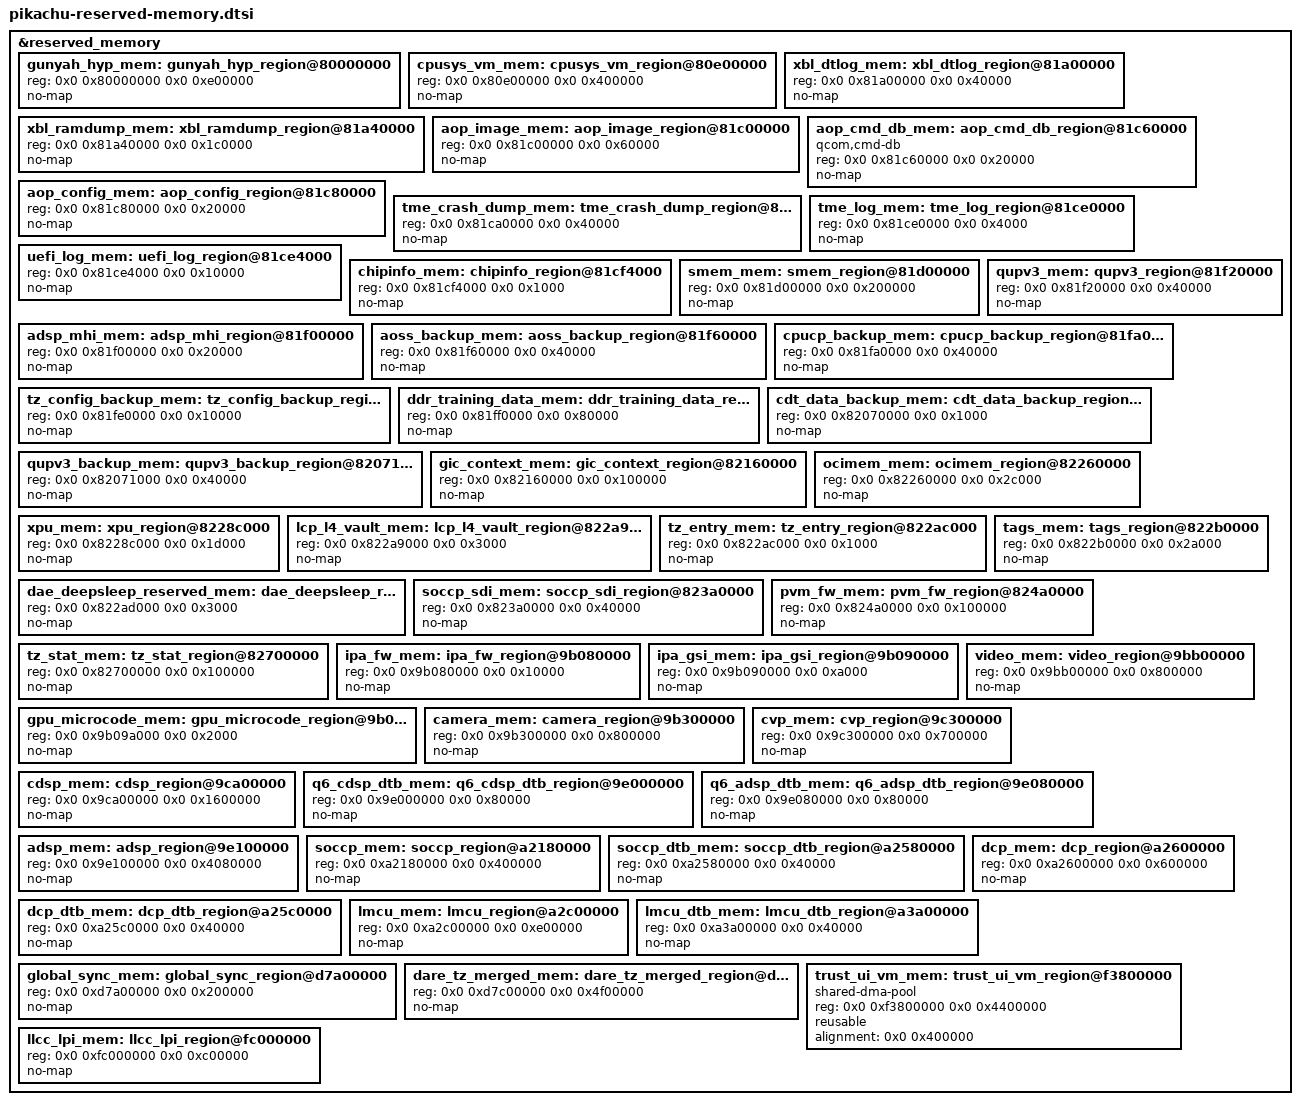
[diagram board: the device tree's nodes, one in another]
// SPDX-License-Identifier: BSD-3-Clause
/*
 * Copyright (c) Qualcomm Technologies, Inc. and/or its subsidiaries.
 */

&reserved_memory {
	gunyah_hyp_mem: gunyah_hyp_region@80000000 {
		reg = <0x0 0x80000000 0x0 0xe00000>;
		no-map;
	};

	cpusys_vm_mem: cpusys_vm_region@80e00000 {
		reg = <0x0 0x80e00000 0x0 0x400000>;
		no-map;
	};

	/* TZ Tags region at 0x81200000 is reclaimed by Linux */

	xbl_dtlog_mem: xbl_dtlog_region@81a00000 {
		reg = <0x0 0x81a00000 0x0 0x40000>;
		no-map;
	};

	xbl_ramdump_mem: xbl_ramdump_region@81a40000 {
		reg = <0x0 0x81a40000 0x0 0x1c0000>;
		no-map;
	};

	aop_image_mem: aop_image_region@81c00000 {
		reg = <0x0 0x81c00000 0x0 0x60000>;
		no-map;
	};

	aop_cmd_db_mem: aop_cmd_db_region@81c60000 {
		compatible = "qcom,cmd-db";
		reg = <0x0 0x81c60000 0x0 0x20000>;
		no-map;
	};

	aop_config_mem: aop_config_region@81c80000 {
		reg = <0x0 0x81c80000 0x0 0x20000>;
		no-map;
	};

	tme_crash_dump_mem: tme_crash_dump_region@81ca0000 {
		reg = <0x0 0x81ca0000 0x0 0x40000>;
		no-map;
	};

	tme_log_mem: tme_log_region@81ce0000 {
		reg = <0x0 0x81ce0000 0x0 0x4000>;
		no-map;
	};

	uefi_log_mem: uefi_log_region@81ce4000 {
		reg = <0x0 0x81ce4000 0x0 0x10000>;
		no-map;
	};

	chipinfo_mem: chipinfo_region@81cf4000 {
		reg = <0x0 0x81cf4000 0x0 0x1000>;
		no-map;
	};

	smem_mem: smem_region@81d00000 {
		reg = <0x0 0x81d00000 0x0 0x200000>;
		no-map;
	};

	adsp_mhi_mem: adsp_mhi_region@81f00000 {
		reg = <0x0 0x81f00000 0x0 0x20000>;
		no-map;
	};

	qupv3_mem: qupv3_region@81f20000 {
		reg = <0x0 0x81f20000 0x0 0x40000>;
		no-map;
	};

	aoss_backup_mem: aoss_backup_region@81f60000 {
		reg = <0x0 0x81f60000 0x0 0x40000>;
		no-map;
	};

	cpucp_backup_mem: cpucp_backup_region@81fa0000 {
		reg = <0x0 0x81fa0000 0x0 0x40000>;
		no-map;
	};

	tz_config_backup_mem: tz_config_backup_region@81fe0000 {
		reg = <0x0 0x81fe0000 0x0 0x10000>;
		no-map;
	};

	ddr_training_data_mem: ddr_training_data_region@81ff0000 {
		reg = <0x0 0x81ff0000 0x0 0x80000>;
		no-map;
	};

	cdt_data_backup_mem: cdt_data_backup_region@82070000 {
		reg = <0x0 0x82070000 0x0 0x1000>;
		no-map;
	};

	qupv3_backup_mem: qupv3_backup_region@82071000 {
		reg = <0x0 0x82071000 0x0 0x40000>;
		no-map;
	};

	gic_context_mem: gic_context_region@82160000 {
		reg = <0x0 0x82160000 0x0 0x100000>;
		no-map;
	};

	ocimem_mem: ocimem_region@82260000 {
		reg = <0x0 0x82260000 0x0 0x2c000>;
		no-map;
	};

	xpu_mem: xpu_region@8228c000 {
		reg = <0x0 0x8228c000 0x0 0x1d000>;
		no-map;
	};

	lcp_l4_vault_mem: lcp_l4_vault_region@822a9000 {
		reg = <0x0 0x822a9000 0x0 0x3000>;
		no-map;
	};

	tz_entry_mem: tz_entry_region@822ac000 {
		reg = <0x0 0x822ac000 0x0 0x1000>;
		no-map;
	};

	dae_deepsleep_reserved_mem: dae_deepsleep_reserved_region@822ad000 {
		reg = <0x0 0x822ad000 0x0 0x3000>;
		no-map;
	};

	tags_mem: tags_region@822b0000 {
		reg = <0x0 0x822b0000 0x0 0x2a000>;
		no-map;
	};

	soccp_sdi_mem: soccp_sdi_region@823a0000 {
		reg = <0x0 0x823a0000 0x0 0x40000>;
		no-map;
	};

	pvm_fw_mem: pvm_fw_region@824a0000 {
		reg = <0x0 0x824a0000 0x0 0x100000>;
		no-map;
	};

	/*
	 * hyp_mem_database_mem is dynamically removed from the RAM
	 * partition tables before boot occurs.
	 */

	tz_stat_mem: tz_stat_region@82700000 {
		reg = <0x0 0x82700000 0x0 0x100000>;
		no-map;
	};

	ipa_fw_mem: ipa_fw_region@9b080000 {
		reg = <0x0 0x9b080000 0x0 0x10000>;
		no-map;
	};

	ipa_gsi_mem: ipa_gsi_region@9b090000 {
		reg = <0x0 0x9b090000 0x0 0xa000>;
		no-map;
	};

	gpu_microcode_mem: gpu_microcode_region@9b09a000 {
		reg = <0x0 0x9b09a000 0x0 0x2000>;
		no-map;
	};

	camera_mem: camera_region@9b300000 {
		reg = <0x0 0x9b300000 0x0 0x800000>;
		no-map;
	};

	video_mem: video_region@9bb00000 {
		reg = <0x0 0x9bb00000 0x0 0x800000>;
		no-map;
	};

	cvp_mem: cvp_region@9c300000 {
		reg = <0x0 0x9c300000 0x0 0x700000>;
		no-map;
	};

	cdsp_mem: cdsp_region@9ca00000 {
		reg = <0x0 0x9ca00000 0x0 0x1600000>;
		no-map;
	};

	q6_cdsp_dtb_mem: q6_cdsp_dtb_region@9e000000 {
		reg = <0x0 0x9e000000 0x0 0x80000>;
		no-map;
	};

	q6_adsp_dtb_mem: q6_adsp_dtb_region@9e080000 {
		reg = <0x0 0x9e080000 0x0 0x80000>;
		no-map;
	};

	adsp_mem: adsp_region@9e100000 {
		reg = <0x0 0x9e100000 0x0 0x4080000>;
		no-map;
	};

	soccp_mem: soccp_region@a2180000 {
		reg = <0x0 0xa2180000 0x0 0x400000>;
		no-map;
	};

	soccp_dtb_mem: soccp_dtb_region@a2580000 {
		reg = <0x0 0xa2580000 0x0 0x40000>;
		no-map;
	};

	dcp_dtb_mem: dcp_dtb_region@a25c0000 {
		reg = <0x0 0xa25c0000 0x0 0x40000>;
		no-map;
	};

	dcp_mem: dcp_region@a2600000 {
		reg = <0x0 0xa2600000 0x0 0x600000>;
		no-map;
	};

	lmcu_mem: lmcu_region@a2c00000 {
		reg = <0x0 0xa2c00000 0x0 0xe00000>;
		no-map;
	};

	lmcu_dtb_mem: lmcu_dtb_region@a3a00000 {
		reg = <0x0 0xa3a00000 0x0 0x40000>;
		no-map;
	};

	/* UEFI region at 0xa7000000 is reclaimed by Linux */

	/* Linux kernel image is loaded at 0xa8000000 */

	global_sync_mem: global_sync_region@d7a00000 {
		reg = <0x0 0xd7a00000 0x0 0x200000>;
		no-map;
	};

	/*
	 * merged sbl_sc_smmu_pt_mem, hyp_ac_config_mem, dare_tz_reserved_1_mem, cpucp_fw_mem,
	 * xbl_sc_mem, dare_tz_reserved_2_mem,  qtee_mem, ta_mem, dare_tz_tags_mem,
	 * dare_tz_reserved_3_mem
	 */
	dare_tz_merged_mem: dare_tz_merged_region@d7c00000 {
		reg = <0x0 0xd7c00000 0x0 0x4f00000>;
		no-map;
	};

	trust_ui_vm_mem: trust_ui_vm_region@f3800000 {
		compatible = "shared-dma-pool";
		reg = <0x0 0xf3800000 0x0 0x4400000>;
		reusable;
		alignment = <0x0 0x400000>;
	};

	llcc_lpi_mem: llcc_lpi_region@fc000000 {
		reg = <0x0 0xfc000000 0x0 0xc00000>;
		no-map;
	};

};
